# SIBG301M114KIH register map
Vendor: Silicon Labs; Series: Si; File version: B
Registers are 32-bit, read-write, reset 0x0 unless marked. A register's access mark holds for its fields unless they carry their own. Offsets are from the block's base; [hi:lo] are bit positions; {n}, {i} and the like mark numbered series.

## LDMAXBAR0_NS — LDMAXBAR0_NS Registers
Base 0x40844000
Same registers: LDMAXBAR0_S 0x50844000
0x00 IPVERSION ro reset 0x3
  [31:0] IPVERSION — IP Version ID
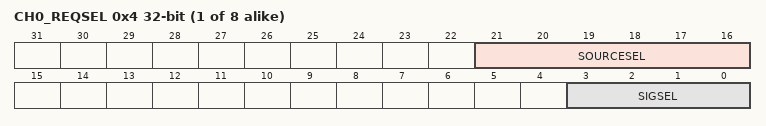
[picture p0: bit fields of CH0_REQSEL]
{0x4+4i} CH{i}_REQSEL (i=0..7)
  [21:16] SOURCESEL — Source Select
  [3:0] SIGSEL — Signal Select

## LEDDRV0_NS — LEDDRV0_NS Registers
Base 0x40880000
Same registers: LEDDRV0_S 0x50880000
0x00 IPVERSION ro reset 0x1
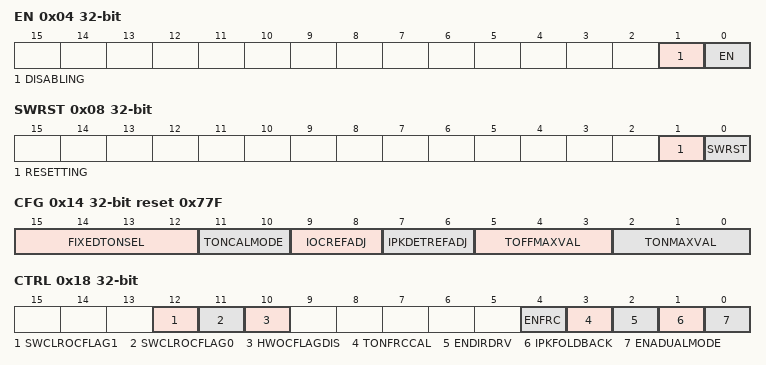
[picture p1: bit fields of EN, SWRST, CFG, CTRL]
0x04 EN
  [1] DISABLING ro — Disablement busy status
  [0] EN — Module enable
0x08 SWRST
  [1] RESETTING ro — Reset busy status
  [0] SWRST wo — Software Reset bit
0x14 CFG reset 0x77F
  [15:12] FIXEDTONSEL — Fixed Ton Select LSBs
  [11:10] TONCALMODE — Ton Calibration Mode Select
    0=ACTIVE (Calibrates only the active channel automatically); 1=BOTH (Calibrates both channels automatically); 2=FORCECAL (Force calibration on active channel when TONFRCCAL is set); 3=FIXED (Use fixed Ton settings (no calibration))
  [9:8] IOCREFADJ — Overcurrent Reference
  [7:6] IPKDETREFADJ — Peak Current Reference
  [5:3] TOFFMAXVAL — Toff Maximum Value
  [2:0] TONMAXVAL — Ton Maximum Value
0x18 CTRL
  [12] SWCLROCFLAG1 — Software Clear OCFLAG channel 1
  [11] SWCLROCFLAG0 — Software Clear OCFLAG channel 0
  [10] HWOCFLAGDIS — Disable Hardware Over current handling
  [4] ENFRC — Enable Force calibration
  [3] TONFRCCAL — Ton Force calibration
  [2] ENDIRDRV — Direct Drive Enable
  [1] IPKFOLDBACK — Peak current foldback enable
  [0] ENADUALMODE — Dual driver mode enable
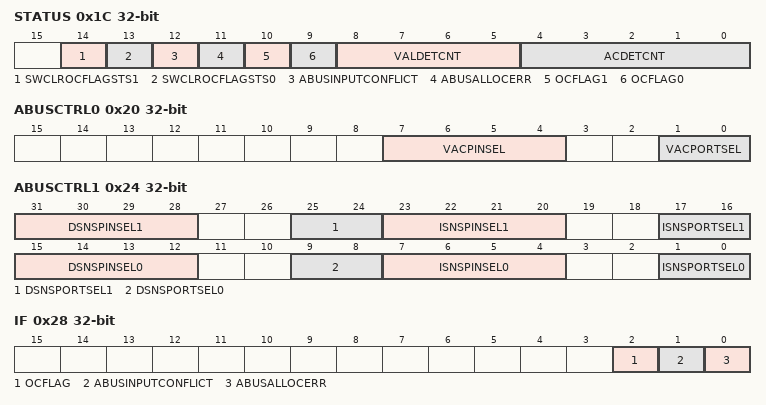
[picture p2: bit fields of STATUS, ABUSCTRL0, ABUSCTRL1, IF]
0x1C STATUS
  [14] SWCLROCFLAGSTS1 — Software OCFLAG1 Clear Pending
  [13] SWCLROCFLAGSTS0 — Software OCFLAG0 Clear Pending
  [12] ABUSINPUTCONFLICT ro — ABUS Input Conflict Status
  [11] ABUSALLOCERR ro — ABUS Allocation Error Status
  [10] OCFLAG1 — Over Current Channel 1
  [9] OCFLAG0 — Over Current Channel 0
  [8:5] VALDETCNT ro — Valley detect counter output
  [4:0] ACDETCNT ro — AC peak detect count value
0x20 ABUSCTRL0
  [7:4] VACPINSEL — VACSENSE Pin Select
  [1:0] VACPORTSEL — VACSENSE Port Select
    0=NONE (VACSENSE not routed to ABUS); 1=PORTC (Route to Port C (Select pin with VACPINSEL)); 2=PORTD (Route to Port D (Select pin with VACPINSEL))
0x24 ABUSCTRL1
  [31:28] DSNSPINSEL1 — DRNSENSE1 Pin Select
  [25:24] DSNSPORTSEL1 — DRNSENSE1 Port Select
    0=NONE (DRNSENSE1 not routed to ABUS); 1=PORTC (Route to Port C (Select pin with DSNSPINSEL1)); 2=PORTD (Route to Port D (Select pin with DSNSPINSEL1))
  [23:20] ISNSPINSEL1 — IPKSENSE1 Pin Select
  [17:16] ISNSPORTSEL1 — IPKSENSE1 Port Select
    0=NONE (IPKSENSE1 not routed to ABUS); 1=PORTC (Route to Port C (Select pin with ISNSPINSEL1)); 2=PORTD (Route to Port D (Select pin with ISNSPINSEL1))
  [15:12] DSNSPINSEL0 — DRNSENSE0 Pin Select
  [9:8] DSNSPORTSEL0 — DRNSENSE0 Port Select
    0=NONE (DRNSENSE0 not routed to ABUS); 1=PORTC (Route to Port C (Select pin with DSNSPINSEL0)); 2=PORTD (Route to Port D (Select pin with DSNSPINSEL0))
  [7:4] ISNSPINSEL0 — IPKSENSE0 Pin Select
  [1:0] ISNSPORTSEL0 — IPKSENSE0 Port Select
    0=NONE (IPKSENSE0 not routed to ABUS); 1=PORTC (Route to Port C (Select pin with ISNSPINSEL0)); 2=PORTD (Route to Port D (Select pin with ISNSPINSEL0))
0x28 IF
  [2] OCFLAG — OCFLAG Interrupt Flag
  [1] ABUSINPUTCONFLICT — ABUS Input Conflict Error Flag
  [0] ABUSALLOCERR — ABUS Port Allocation Error Flag
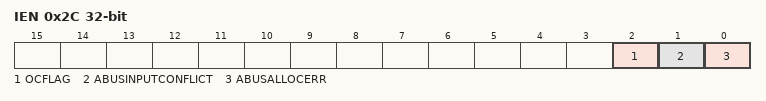
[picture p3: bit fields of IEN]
0x2C IEN
  [2] OCFLAG — OCFLAG Interrupt Enable
  [1] ABUSINPUTCONFLICT — ABUS Input Conflict Interrupt Enable
  [0] ABUSALLOCERR — ABUS Allocation Error Interrupt Enable

## LFRCO_NS — LFRCO_NS Registers
Base 0x40824000
Same registers: LFRCO_S 0x50824000
0x00 IPVERSION ro reset 0x4 — Contains the LFRCO ip version
  [31:0] IPVERSION — IP version ID
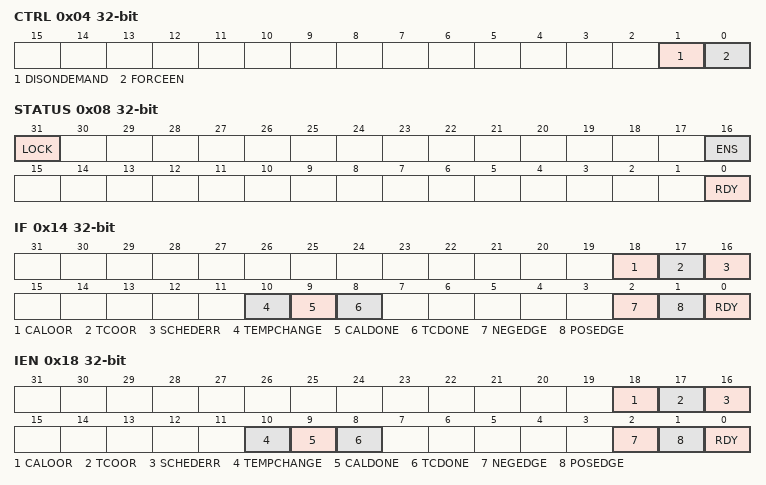
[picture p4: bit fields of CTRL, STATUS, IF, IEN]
0x04 CTRL — Control register
  [1] DISONDEMAND — Disable On-Demand
  [0] FORCEEN — Force Enable
0x08 STATUS ro
  [31] LOCK — Lock Status
    0=UNLOCKED (Access to configuration registers not locked); 1=LOCKED (Access to configuration registers locked)
  [16] ENS — Enabled Status
  [0] RDY — Ready Status
0x14 IF — Interrupt flag register
  [18] CALOOR — Calibration Out Of Range Flag
  [17] TCOOR — Temperature Check Out Of Range Flag
  [16] SCHEDERR — Scheduling Error Flag
  [10] TEMPCHANGE — Temperature Change Flag
  [9] CALDONE — Calibration Done Flag
  [8] TCDONE — Temperature Check Done Flag
  [2] NEGEDGE — Falling Edge Flag
  [1] POSEDGE — Rising Edge Flag
  [0] RDY — Ready Flag
0x18 IEN — Interrupt enable register
  [18] CALOOR — Calibration Out Of Range Enable
  [17] TCOOR — Temperature Check Out Of Range Enable
  [16] SCHEDERR — Scheduling Error Enable
  [10] TEMPCHANGE — Temperature Change Enable
  [9] CALDONE — Calibration Done Enable
  [8] TCDONE — Temperature Check Done Enable
  [2] NEGEDGE — Falling Edge Enable
  [1] POSEDGE — Rising Edge Enable
  [0] RDY — Ready Enable
0x20 LOCK wo — Configuration lock register. Locks and unlocks access to configuration registers.
  [15:0] LOCKKEY
    0=LOCK (Lock Configuration Registers); 0xF93=UNLOCK (Unlock Configuration Registers)
0x24 CFG — Configuration register
  [0] HIGHPRECEN — High Precision Enable
0x2C NOMCAL reset 0x5B8D8 — Nominal calibration register
  [20:0] NOMCALCNT — Nominal Calibration Count
0x30 NOMCALINV reset 0x597A — Nominal calibration inverted register
  [16:0] NOMCALCNTINV — Nominal Calibration Count Inverted
0x34 CMD wo — Command register
  [0] REDUCETCINT — Reduce Temperature Check Interval
